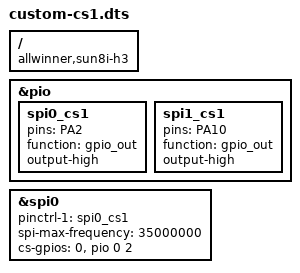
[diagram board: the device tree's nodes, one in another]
/dts-v1/;
/plugin/;

/ {
	compatible = "allwinner,sun8i-h3";

	fragment@0 {
		target = <&pio>;
		__overlay__ {
			spi0_cs1: spi0_cs1 {
				pins = "PA2";
				function = "gpio_out";
				output-high;
			};

			spi1_cs1: spi1_cs1 {
				pins = "PA10";
				function = "gpio_out";
				output-high;
			};
		};
	};

	fragment@1 {
		target = <&spi0>;
		__overlay__ {
			pinctrl-names = "default", "default";
			pinctrl-1 = <&spi0_cs1>;
                        spi-max-frequency = <35000000>;
			cs-gpios = <0>, <&pio 0 2 0>; /* PA2 */
		};
	};
/*
	fragment@2 {
		target = <&spi1>;
		__overlay__ {
			pinctrl-names = "default", "default";
			pinctrl-1 = <&spi1_cs1>;
//			spi-max-frequency = <32000000>;
			cs-gpios = <0>, <&pio 0 10 0>; /* PA10 */
//		};
//	};
};
